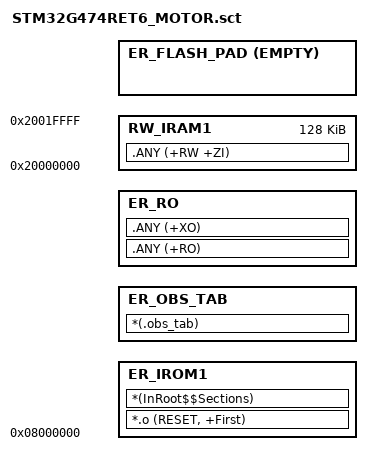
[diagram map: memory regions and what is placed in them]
; Custom scatter — do NOT enable "Use Memory Layout from Target Dialog" in Keil Linker tab.
; App 508 KB (0x7F000); factory_nvm @ 0x0807F000 (4 KB, not linked here).
; ER_OBS_TAB 必须在吞 RO 的 .ANY 之前，否则表项进不了独立段。

LR_IROM1 0x08000000 0x0007F000  {
  ER_IROM1 0x08000000  {
   *.o (RESET, +First)
   *(InRoot$$Sections)
  }
  ER_OBS_TAB +0 {
   *(.obs_tab)
  }
  ER_RO +0 {
   .ANY (+RO)
   .ANY (+XO)
  }
  RW_IRAM1 0x20000000 0x00020000  {
   .ANY (+RW +ZI)
  }
  ER_FLASH_PAD +0 FILL 0xFFFFFFFF ALIGN 0x800 EMPTY 0 { }
}
